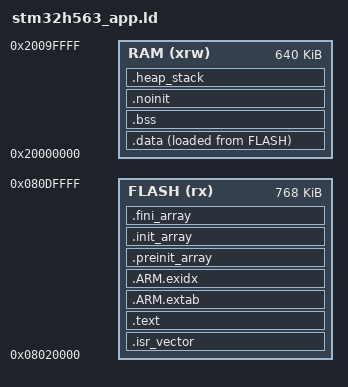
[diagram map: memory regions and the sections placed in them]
ENTRY(Reset_Handler)

_Min_Heap_Size = 0;
_Min_Stack_Size = 0x800;

MEMORY
{
  FLASH (rx)  : ORIGIN = 0x08020000, LENGTH = 768K
  RAM   (xrw) : ORIGIN = 0x20000000, LENGTH = 640K
}

_estack = ORIGIN(RAM) + LENGTH(RAM);
_sstack = _estack - _Min_Stack_Size;

SECTIONS
{
  .isr_vector : { . = ALIGN(256); KEEP(*(.isr_vector)) . = ALIGN(4); } > FLASH
  .text :
  {
    . = ALIGN(4);
    *(.text .text*)
    *(.rodata .rodata*)
    KEEP(*(.init))
    KEEP(*(.fini))
    . = ALIGN(4);
    _etext = .;
  } > FLASH
  .ARM.extab : { *(.ARM.extab* .gnu.linkonce.armextab.*) } > FLASH
  .ARM.exidx :
  {
    __exidx_start = .;
    *(.ARM.exidx*)
    __exidx_end = .;
  } > FLASH
  .preinit_array :
  {
    PROVIDE_HIDDEN(__preinit_array_start = .);
    KEEP(*(.preinit_array*))
    PROVIDE_HIDDEN(__preinit_array_end = .);
  } > FLASH
  .init_array :
  {
    PROVIDE_HIDDEN(__init_array_start = .);
    KEEP(*(SORT(.init_array.*))) KEEP(*(.init_array*))
    PROVIDE_HIDDEN(__init_array_end = .);
  } > FLASH
  .fini_array :
  {
    PROVIDE_HIDDEN(__fini_array_start = .);
    KEEP(*(SORT(.fini_array.*))) KEEP(*(.fini_array*))
    PROVIDE_HIDDEN(__fini_array_end = .);
  } > FLASH
  _sidata = LOADADDR(.data);
  .data :
  {
    . = ALIGN(4);
    _sdata = .;
    *(.data .data*)
    . = ALIGN(4);
    _edata = .;
  } > RAM AT > FLASH
  .bss (NOLOAD) :
  {
    . = ALIGN(8);
    _sbss = .;
    *(.bss .bss*) *(COMMON)
    . = ALIGN(8);
    _ebss = .;
  } > RAM
  .noinit (NOLOAD) :
  {
    . = ALIGN(8);
    *(.noinit .noinit*)
    . = ALIGN(8);
  } > RAM
  .heap_stack (NOLOAD) :
  {
    . = ALIGN(8);
    PROVIDE(end = .);
    PROVIDE(_end = .);
    . += _Min_Heap_Size;
    . += _Min_Stack_Size;
    . = ALIGN(8);
  } > RAM
  /DISCARD/ : { *(.note.GNU-stack) }
}

ASSERT(ORIGIN(FLASH) == 0x08020000, "application slot origin changed")
ASSERT((_edata - _sdata) + (_ebss - _sbss) + _Min_Stack_Size <= LENGTH(RAM),
       "RAM budget exceeded")
